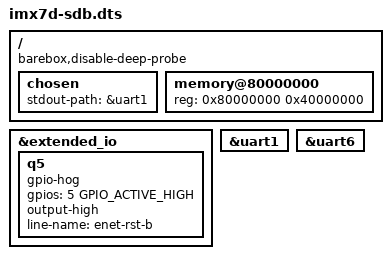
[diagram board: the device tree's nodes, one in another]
/*
 * The code contained herein is licensed under the GNU General Public
 * License. You may obtain a copy of the GNU General Public License
 * Version 2 or later at the following locations:
 *
 * http://www.opensource.org/licenses/gpl-license.html
 * http://www.gnu.org/copyleft/gpl.html
 */

#include <arm/nxp/imx/imx7d-sdb.dts>

/ {
	barebox,disable-deep-probe;

	chosen {
		stdout-path = &uart1;
	};

	memory@80000000 {
		device_type = "memory";
		reg = <0x80000000 0x40000000>;
	};
};

&extended_io {
	q5 {
		gpio-hog;
		gpios = <5 GPIO_ACTIVE_HIGH>;
		output-high;
		line-name = "enet-rst-b";
	};
};

/* FIXME: barebox serial is broken when barebox applies requested reparenting */
&uart1 {
	/delete-property/ assigned-clocks;
	/delete-property/ assigned-clock-parents;
};

&uart6 {
	/delete-property/ assigned-clocks;
	/delete-property/ assigned-clock-parents;
};
